VERSION ""

NS_ :

BS_:

BU_: XXX

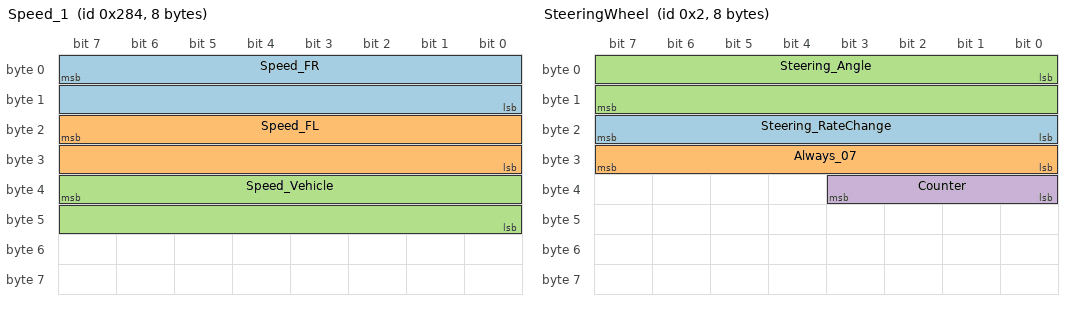
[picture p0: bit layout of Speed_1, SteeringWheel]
BO_ 644 Speed_1: 8 XXX
 SG_ Speed_FR : 7|16@0+ (0.0118,0) [0|65535] "" XXX
 SG_ Speed_FL : 23|16@0+ (0.0118,0) [0|65535] "" XXX
 SG_ Speed_Vehicle : 39|16@0+ (0.0245,0) [0|65535] "" XXX

BO_ 645 WheelspeedRear: 8 XXX
 SG_ RR : 7|16@0+ (0.00555,0) [0|65535] "KPH" XXX
 SG_ RL : 23|16@0+ (0.00555,0) [0|65535] "KPH" XXX

BO_ 768 STEER_TORQUE: 2 XXX
 SG_ STEERING_TORQUE : 6|7@0+ (1,0) [0|127] "" XXX
 SG_ DriverTouchingWheel : 15|1@0+ (-1,1) [0|7] "" XXX

BO_ 459 Maybe_RegenBraking: 8 XXX

BO_ 372 Maybe_Gear_Selector: 8 XXX
 SG_ Counter : 35|4@0+ (1,0) [0|15] "" XXX

BO_ 374 Maybe_Motor_RPM_or_Speed: 8 XXX
 SG_ Counter : 51|4@0+ (1,0) [0|15] "" XXX

BO_ 460 Maybe_Brake_Related: 8 XXX

BO_ 2 SteeringWheel: 8 XXX
 SG_ Steering_RateChange : 16|8@1+ (1,0) [0|255] "" XXX
 SG_ Always_07 : 24|8@1+ (1,0) [0|255] "" XXX
 SG_ Steering_Angle : 0|16@1- (-0.1,0) [0|65535] "" XXX
 SG_ Counter : 32|4@1+ (1,0) [0|15] "" XXX

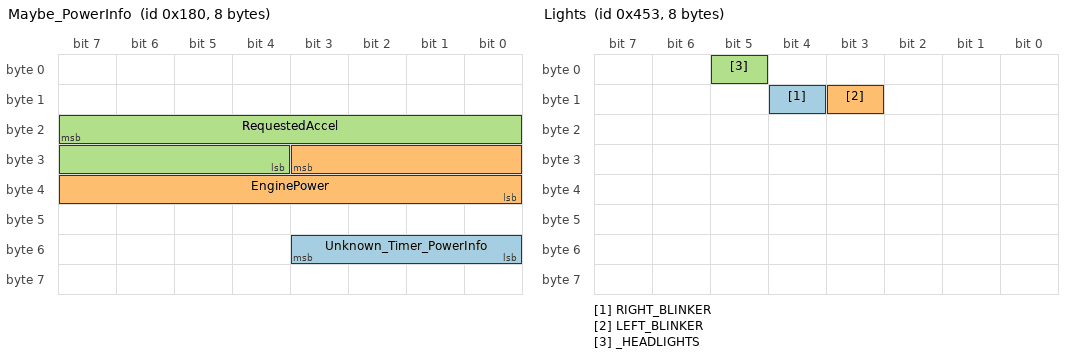
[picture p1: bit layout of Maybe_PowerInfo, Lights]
BO_ 384 Maybe_PowerInfo: 8 XXX
 SG_ Unknown_Timer_PowerInfo : 51|4@0+ (1,0) [0|15] "" XXX
 SG_ EnginePower : 27|12@0- (1,0) [0|1] "" XXX
 SG_ RequestedAccel : 23|12@0- (1,0) [0|4294967295] "" XXX

BO_ 1107 Lights: 8 XXX
 SG_ RIGHT_BLINKER : 12|1@0+ (1,0) [0|1] "" XXX
 SG_ LEFT_BLINKER : 11|1@0+ (1,0) [0|1] "" XXX
 SG_ _HEADLIGHTS : 5|1@0+ (1,0) [0|1] "" XXX

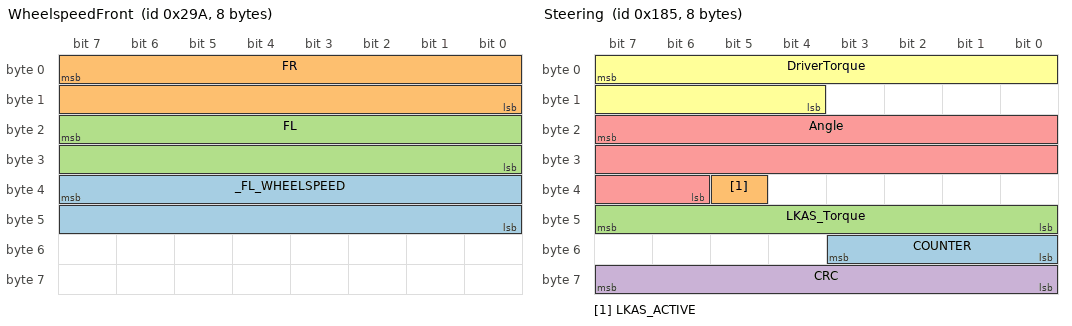
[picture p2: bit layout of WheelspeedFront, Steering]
BO_ 666 WheelspeedFront: 8 XXX
 SG_ _FL_WHEELSPEED : 39|16@0+ (0.01014,0) [0|65535] "" XXX
 SG_ FR : 7|16@0+ (0.00555,0) [0|65535] "KPH" XXX
 SG_ FL : 23|16@0+ (0.00555,0) [0|65535] "KPH" XXX

BO_ 389 Steering: 8 XXX
 SG_ COUNTER : 51|4@0+ (1,0) [0|15] "" XXX
 SG_ LKAS_ACTIVE : 37|1@0+ (1,0) [0|3] "" XXX
 SG_ LKAS_Torque : 47|8@0+ (1,0) [0|255] "" XXX
 SG_ CRC : 63|8@0+ (1,0) [0|127] "" XXX
 SG_ Angle : 23|18@0+ (-0.01,1310) [0|262143] "" XXX
 SG_ DriverTorque : 7|12@0+ (1,-2047) [0|4095] "" XXX

BO_ 851 SPEED_RELATED: 8 XXX
 SG_ SPEED_RELATED : 7|16@0+ (0.01014,0) [0|65535] "" XXX

BO_ 386 Accelerator: 8 XXX
 SG_ Accelerator : 38|7@0+ (1,0) [0|127] "" XXX

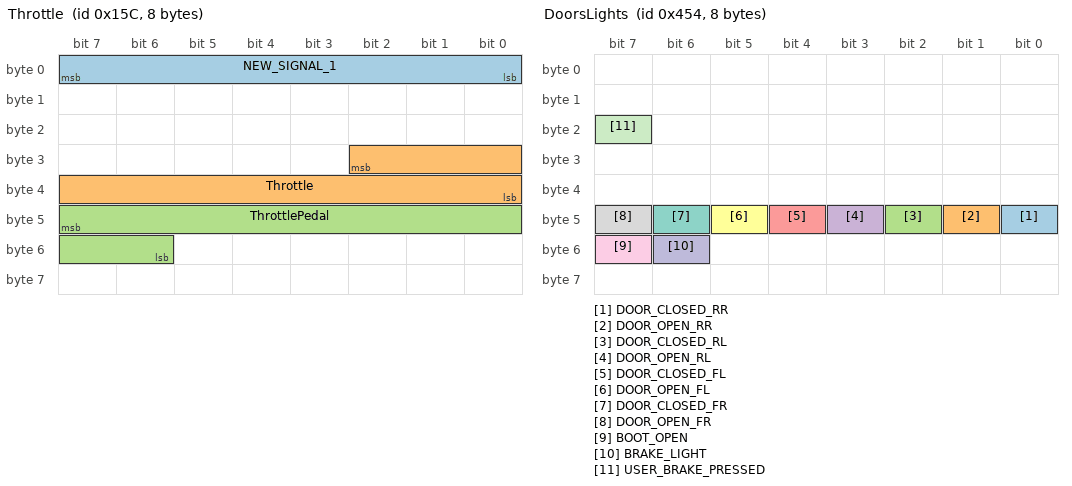
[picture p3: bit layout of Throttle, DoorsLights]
BO_ 348 Throttle: 8 XXX
 SG_ NEW_SIGNAL_1 : 7|8@0+ (1,0) [0|255] "" XXX
 SG_ Throttle : 26|11@0+ (1,0) [0|2047] "" XXX
 SG_ ThrottlePedal : 47|10@0+ (1,0) [0|1023] "" XXX

BO_ 523 CruiseThrottle: 6 XXX
 SG_ PROPILOT_BUTTON : 8|1@0+ (1,0) [0|1] "" XXX
 SG_ CANCEL_BUTTON : 9|1@0+ (1,0) [0|1] "" XXX
 SG_ GAS_PEDAL_INVERTED : 37|10@0+ (1,0) [0|1023] "" XXX
 SG_ SET_BUTTON : 11|1@0+ (1,0) [0|1] "" XXX
 SG_ RES_BUTTON : 12|1@0+ (1,0) [0|1] "" XXX
 SG_ FOLLOW_DISTANCE_BUTTON : 10|1@0+ (1,0) [0|1] "" XXX
 SG_ NO_BUTTON_PRESSED : 13|1@0+ (1,0) [0|1] "" XXX
 SG_ GAS_PEDAL : 31|10@0+ (1,0) [0|255] "" XXX
 SG_ USER_BRAKE_PRESSED : 21|1@0+ (1,0) [0|1] "" XXX
 SG_ USER_BRAKE_PRESSED_INVERTED : 22|1@0+ (1,0) [0|3] "" XXX
 SG_ NEW_SIGNAL_2 : 23|1@0+ (1,0) [0|1] "" XXX
 SG_ unsure2 : 43|4@0+ (1,0) [0|1] "" XXX
 SG_ unsure1 : 7|16@0+ (1,0) [0|15] "" XXX
 SG_ GAS_PRESSED_INVERTED : 20|1@0+ (1,0) [0|255] "" XXX
 SG_ COUNTER : 17|2@0+ (1,0) [0|3] "" XXX
 SG_ unsure3 : 19|2@0+ (1,0) [0|3] "" XXX

BO_ 1108 DoorsLights: 8 XXX
 SG_ DOOR_CLOSED_RR : 40|1@0+ (1,0) [0|1] "" XXX
 SG_ DOOR_OPEN_RR : 41|1@0+ (1,0) [0|1] "" XXX
 SG_ DOOR_CLOSED_RL : 42|1@0+ (1,0) [0|1] "" XXX
 SG_ DOOR_OPEN_RL : 43|1@0+ (1,0) [0|1] "" XXX
 SG_ DOOR_CLOSED_FL : 44|1@0+ (1,0) [0|1] "" XXX
 SG_ DOOR_OPEN_FL : 45|1@0+ (1,0) [0|1] "" XXX
 SG_ DOOR_CLOSED_FR : 46|1@0+ (1,0) [0|3] "" XXX
 SG_ DOOR_OPEN_FR : 47|1@0+ (1,0) [0|3] "" XXX
 SG_ BOOT_OPEN : 55|1@0+ (1,0) [0|1] "" XXX
 SG_ BRAKE_LIGHT : 54|1@0+ (1,0) [0|1] "" XXX
 SG_ USER_BRAKE_PRESSED : 23|1@0+ (1,0) [0|1] "" XXX

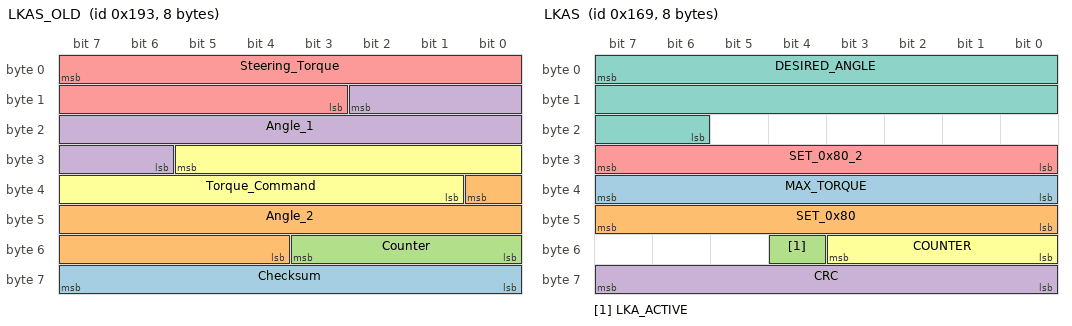
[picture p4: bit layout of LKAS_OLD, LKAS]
BO_ 403 LKAS_OLD: 8 XXX
 SG_ Checksum : 63|8@0+ (1,0) [0|255] "" XXX
 SG_ Angle_2 : 32|13@0+ (1,-4000) [0|63] "" XXX
 SG_ Counter : 51|4@0+ (1,0) [0|15] "" XXX
 SG_ Angle_1 : 10|13@0+ (0.12,-480) [0|65535] "" XXX
 SG_ Steering_Torque : 7|13@0+ (-1,4000) [0|65535] "" XXX
 SG_ Torque_Command : 29|13@0+ (1,-4000) [0|255] "" XXX

BO_ 361 LKAS: 8 XXX
 SG_ MAX_TORQUE : 39|8@0+ (1,0) [0|255] "" XXX
 SG_ SET_0x80 : 47|8@0+ (1,0) [0|255] "" XXX
 SG_ LKA_ACTIVE : 52|1@0+ (1,0) [0|15] "" XXX
 SG_ CRC : 63|8@0+ (1,0) [0|255] "" XXX
 SG_ SET_0x80_2 : 31|8@0+ (1,0) [0|255] "" XXX
 SG_ COUNTER : 51|4@0+ (1,0) [0|15] "" XXX
 SG_ DESIRED_ANGLE : 7|18@0+ (-0.01,1310) [0|255] "" XXX

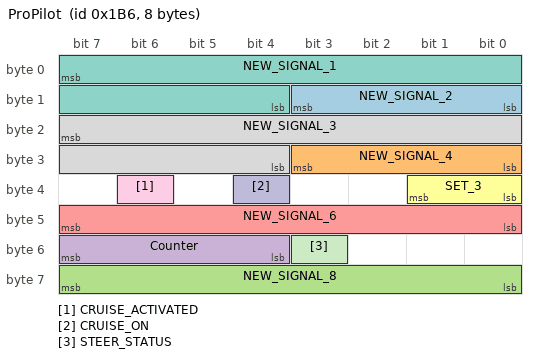
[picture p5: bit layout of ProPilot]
BO_ 438 ProPilot: 8 XXX
 SG_ NEW_SIGNAL_2 : 11|4@0+ (1,0) [0|255] "" XXX
 SG_ NEW_SIGNAL_4 : 27|4@0+ (1,0) [0|255] "" XXX
 SG_ NEW_SIGNAL_8 : 63|8@0+ (1,0) [0|7] "" XXX
 SG_ Counter : 55|4@0+ (1,0) [0|255] "" XXX
 SG_ NEW_SIGNAL_6 : 47|8@0+ (1,0) [0|255] "" XXX
 SG_ SET_3 : 33|2@0+ (1,0) [0|15] "" XXX
 SG_ NEW_SIGNAL_1 : 7|12@0- (1,0) [0|255] "" XXX
 SG_ NEW_SIGNAL_3 : 23|12@0- (-1,0) [0|255] "" XXX
 SG_ CRUISE_ACTIVATED : 38|1@0+ (1,0) [0|3] "" XXX
 SG_ CRUISE_ON : 36|1@0+ (1,0) [0|255] "" XXX
 SG_ STEER_STATUS : 51|1@0+ (1,0) [0|3] "" XXX

BO_ 397 _GEAR: 8 XXX
 SG_ GEAR : 27|4@0+ (1,0) [0|15] "" XXX

BO_ 1273 _SEATBELT: 7 XXX
 SG_ DRIVERS_SEATBELT : 25|1@0+ (1,0) [0|1] "" XXX

BO_ 665 _ESP: 8 XXX
 SG_ ESP_DISABLED : 24|1@0+ (1,0) [0|1] "" XXX

BO_ 1055 GEARBOX: 2 XXX
 SG_ SPORTS_MODE : 13|1@0+ (1,0) [0|1] "" XXX
 SG_ GEAR_SHIFTER : 5|3@0+ (1,0) [0|255] "" XXX

VAL_ 1055 GEAR_SHIFTER 6 "L" 4 "D" 3 "N" 2 "R" 1 "P" ;
